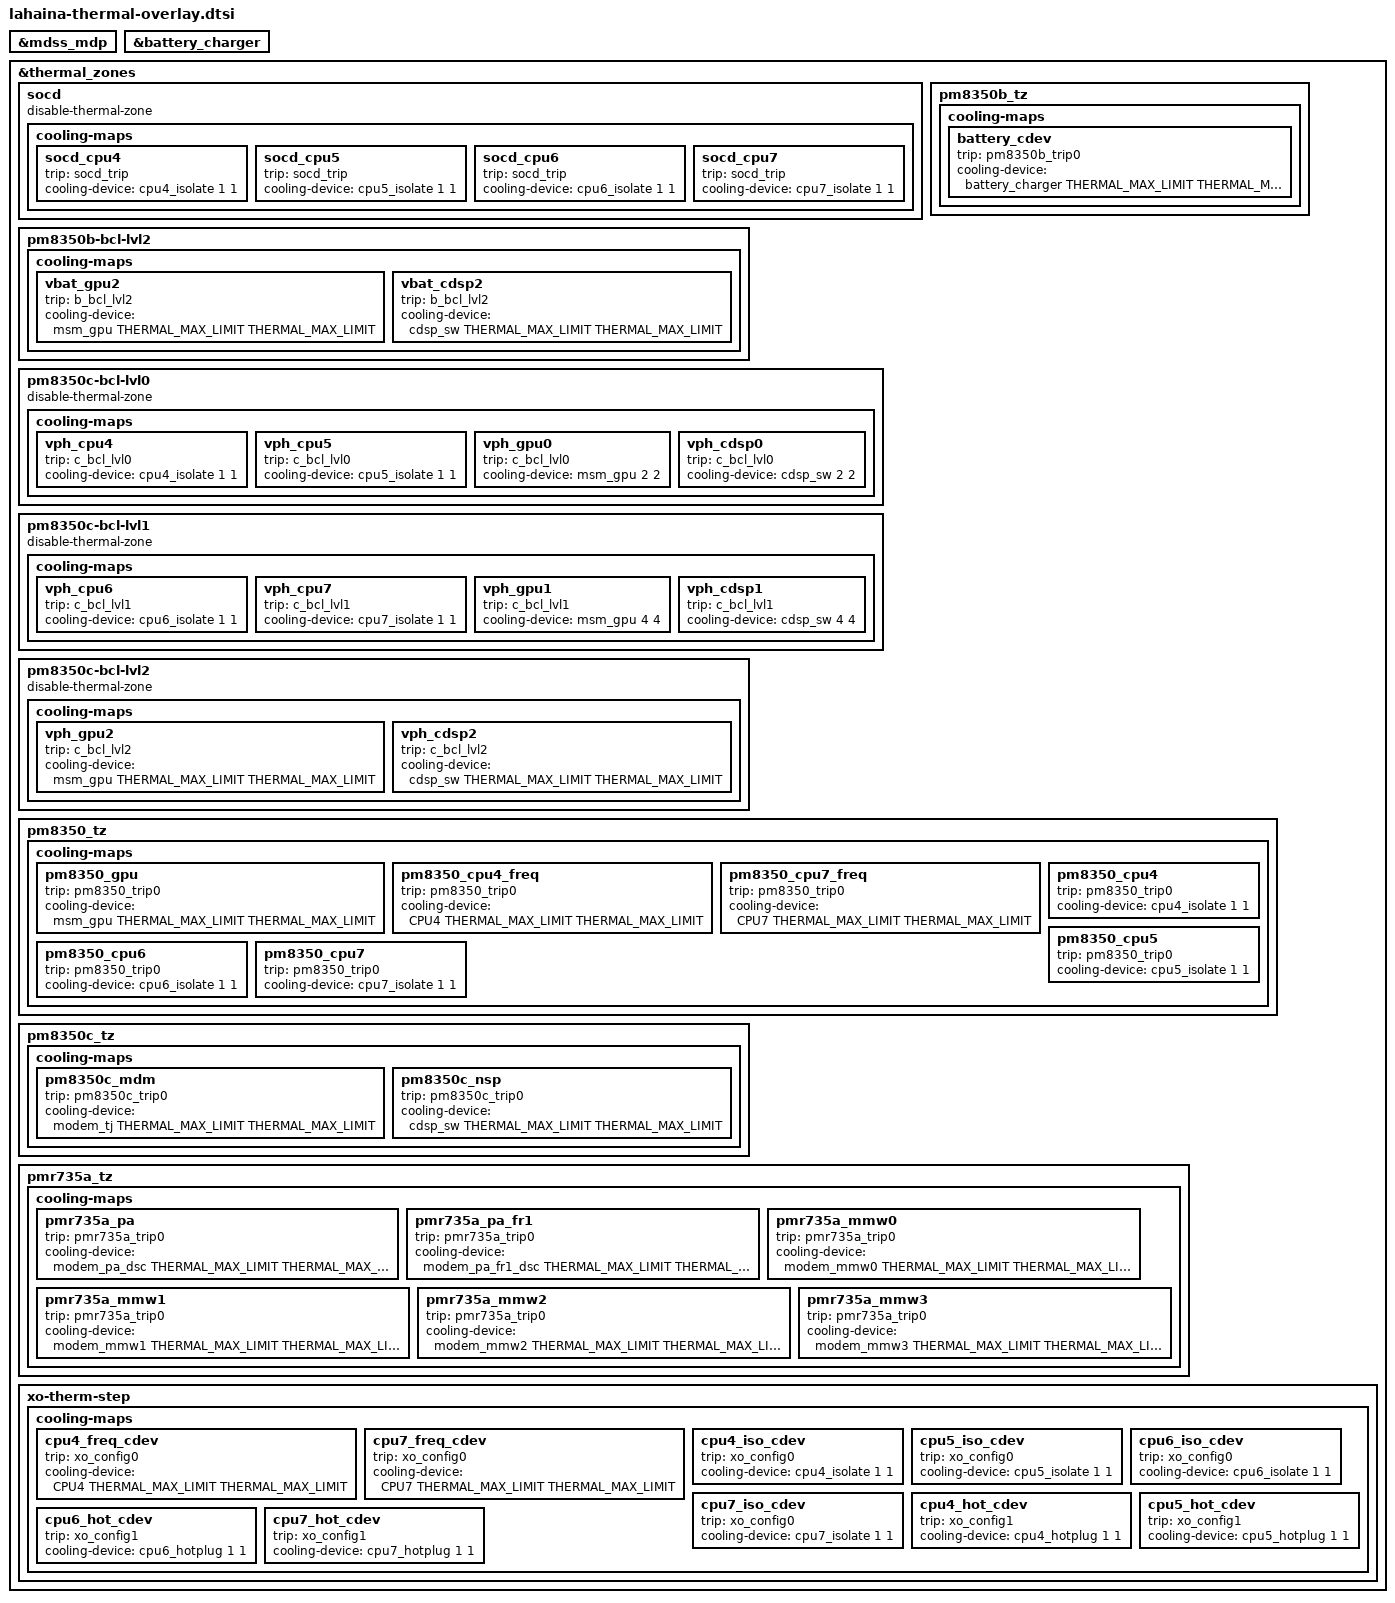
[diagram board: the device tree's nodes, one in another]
#include <dt-bindings/thermal/thermal_qti.h>

&mdss_mdp {
	#cooling-cells = <2>;
};

&battery_charger {
	#cooling-cells = <2>;
};

&thermal_zones {
	socd {
		disable-thermal-zone;
		cooling-maps {
			socd_cpu4 {
				trip = <&socd_trip>;
				cooling-device = <&cpu4_isolate 1 1>;
			};

			socd_cpu5 {
				trip = <&socd_trip>;
				cooling-device = <&cpu5_isolate 1 1>;
			};

			socd_cpu6 {
				trip = <&socd_trip>;
				cooling-device = <&cpu6_isolate 1 1>;
			};

			socd_cpu7 {
				trip = <&socd_trip>;
				cooling-device = <&cpu7_isolate 1 1>;
			};
		};
	};


/*	pm8350b-bcl-lvl0 {
		cooling-maps {
			vbat_cpu4 {
				trip = <&b_bcl_lvl0>;
				cooling-device = <&cpu4_isolate 1 1>;
			};

			vbat_cpu5 {
				trip = <&b_bcl_lvl0>;
				cooling-device = <&cpu5_isolate 1 1>;
			};

			vbat_gpu0 {
				trip = <&b_bcl_lvl0>;
				cooling-device = <&msm_gpu 2 2>;
			};

			vbat_cdsp0 {
				trip = <&b_bcl_lvl0>;
				cooling-device = <&cdsp_sw 2 2>;
			};
		};
	};

	pm8350b-bcl-lvl1 {
		cooling-maps {
			vbat_cpu6 {
				trip = <&b_bcl_lvl1>;
				cooling-device = <&cpu6_isolate 1 1>;
			};

			vbat_cpu7 {
				trip = <&b_bcl_lvl1>;
				cooling-device = <&cpu7_isolate 1 1>;
			};

			vbat_gpu1 {
				trip = <&b_bcl_lvl1>;
				cooling-device = <&msm_gpu 4 4>;
			};

			vbat_cdsp1 {
				trip = <&b_bcl_lvl1>;
				cooling-device = <&cdsp_sw 4 4>;
			};
		};
	};
*/
	pm8350b-bcl-lvl2 {
		cooling-maps {
			vbat_gpu2 {
				trip = <&b_bcl_lvl2>;
				cooling-device = <&msm_gpu THERMAL_MAX_LIMIT
							THERMAL_MAX_LIMIT>;
			};

			vbat_cdsp2 {
				trip = <&b_bcl_lvl2>;
				cooling-device = <&cdsp_sw THERMAL_MAX_LIMIT
							THERMAL_MAX_LIMIT>;
			};
		};
	};

	pm8350c-bcl-lvl0 {
		disable-thermal-zone;
		cooling-maps {
			vph_cpu4 {
				trip = <&c_bcl_lvl0>;
				cooling-device = <&cpu4_isolate 1 1>;
			};

			vph_cpu5 {
				trip = <&c_bcl_lvl0>;
				cooling-device = <&cpu5_isolate 1 1>;
			};

			vph_gpu0 {
				trip = <&c_bcl_lvl0>;
				cooling-device = <&msm_gpu 2 2>;
			};

			vph_cdsp0 {
				trip = <&c_bcl_lvl0>;
				cooling-device = <&cdsp_sw 2 2>;
			};
		};
	};

	pm8350c-bcl-lvl1 {
		disable-thermal-zone;
		cooling-maps {
			vph_cpu6 {
				trip = <&c_bcl_lvl1>;
				cooling-device = <&cpu6_isolate 1 1>;
			};

			vph_cpu7 {
				trip = <&c_bcl_lvl1>;
				cooling-device = <&cpu7_isolate 1 1>;
			};

			vph_gpu1 {
				trip = <&c_bcl_lvl1>;
				cooling-device = <&msm_gpu 4 4>;
			};

			vph_cdsp1 {
				trip = <&c_bcl_lvl1>;
				cooling-device = <&cdsp_sw 4 4>;
			};
		};
	};

	pm8350c-bcl-lvl2 {
		disable-thermal-zone;
		cooling-maps {
			vph_gpu2 {
				trip = <&c_bcl_lvl2>;
				cooling-device = <&msm_gpu THERMAL_MAX_LIMIT
							THERMAL_MAX_LIMIT>;
			};

			vph_cdsp2 {
				trip = <&c_bcl_lvl2>;
				cooling-device = <&cdsp_sw THERMAL_MAX_LIMIT
							THERMAL_MAX_LIMIT>;
			};
		};
	};

	pm8350b_tz {
		cooling-maps {
			battery_cdev {
				trip = <&pm8350b_trip0>;
				cooling-device = <&battery_charger
							THERMAL_MAX_LIMIT
							THERMAL_MAX_LIMIT>;
			};
		};
	};

	pm8350_tz {
		cooling-maps {
			pm8350_gpu {
				trip = <&pm8350_trip0>;
				cooling-device = <&msm_gpu THERMAL_MAX_LIMIT
							THERMAL_MAX_LIMIT>;
			};

			pm8350_cpu4_freq {
				trip = <&pm8350_trip0>;
				cooling-device = <&CPU4 THERMAL_MAX_LIMIT
							THERMAL_MAX_LIMIT>;
			};

			pm8350_cpu7_freq {
				trip = <&pm8350_trip0>;
				cooling-device = <&CPU7 THERMAL_MAX_LIMIT
							THERMAL_MAX_LIMIT>;
			};

			pm8350_cpu4 {
				trip = <&pm8350_trip0>;
				cooling-device = <&cpu4_isolate 1 1>;
			};

			pm8350_cpu5 {
				trip = <&pm8350_trip0>;
				cooling-device = <&cpu5_isolate 1 1>;
			};

			pm8350_cpu6 {
				trip = <&pm8350_trip0>;
				cooling-device = <&cpu6_isolate 1 1>;
			};

			pm8350_cpu7 {
				trip = <&pm8350_trip0>;
				cooling-device = <&cpu7_isolate 1 1>;
			};
		};
	};

	pm8350c_tz {
		cooling-maps {
			pm8350c_mdm {
				trip = <&pm8350c_trip0>;
				cooling-device = <&modem_tj THERMAL_MAX_LIMIT
							THERMAL_MAX_LIMIT>;
			};

			pm8350c_nsp {
				trip = <&pm8350c_trip0>;
				cooling-device = <&cdsp_sw THERMAL_MAX_LIMIT
							THERMAL_MAX_LIMIT>;
			};
		};
	};

	pmr735a_tz {
		cooling-maps {
			pmr735a_pa {
				trip = <&pmr735a_trip0>;
				cooling-device = <&modem_pa_dsc
							THERMAL_MAX_LIMIT
							THERMAL_MAX_LIMIT>;
			};

			pmr735a_pa_fr1 {
				trip = <&pmr735a_trip0>;
				cooling-device = <&modem_pa_fr1_dsc
							THERMAL_MAX_LIMIT
							THERMAL_MAX_LIMIT>;
			};

			pmr735a_mmw0 {
				trip = <&pmr735a_trip0>;
				cooling-device = <&modem_mmw0 THERMAL_MAX_LIMIT
							THERMAL_MAX_LIMIT>;
			};

			pmr735a_mmw1 {
				trip = <&pmr735a_trip0>;
				cooling-device = <&modem_mmw1 THERMAL_MAX_LIMIT
							THERMAL_MAX_LIMIT>;
			};

			pmr735a_mmw2 {
				trip = <&pmr735a_trip0>;
				cooling-device = <&modem_mmw2 THERMAL_MAX_LIMIT
							THERMAL_MAX_LIMIT>;
			};

			pmr735a_mmw3 {
				trip = <&pmr735a_trip0>;
				cooling-device = <&modem_mmw3 THERMAL_MAX_LIMIT
							THERMAL_MAX_LIMIT>;
			};
		};
	};

	xo-therm-step {
		cooling-maps {
			cpu4_freq_cdev {
				trip = <&xo_config0>;
				cooling-device = <&CPU4 THERMAL_MAX_LIMIT
							THERMAL_MAX_LIMIT>;
			};

			cpu7_freq_cdev {
				trip = <&xo_config0>;
				cooling-device = <&CPU7 THERMAL_MAX_LIMIT
							THERMAL_MAX_LIMIT>;
			};

			cpu4_iso_cdev {
				trip = <&xo_config0>;
				cooling-device = <&cpu4_isolate 1 1>;
			};

			cpu5_iso_cdev {
				trip = <&xo_config0>;
				cooling-device = <&cpu5_isolate 1 1>;
			};

			cpu6_iso_cdev {
				trip = <&xo_config0>;
				cooling-device = <&cpu6_isolate 1 1>;
			};

			cpu7_iso_cdev {
				trip = <&xo_config0>;
				cooling-device = <&cpu7_isolate 1 1>;
			};

			cpu4_hot_cdev {
				trip = <&xo_config1>;
				cooling-device = <&cpu4_hotplug 1 1>;
			};

			cpu5_hot_cdev {
				trip = <&xo_config1>;
				cooling-device = <&cpu5_hotplug 1 1>;
			};

			cpu6_hot_cdev {
				trip = <&xo_config1>;
				cooling-device = <&cpu6_hotplug 1 1>;
			};

			cpu7_hot_cdev {
				trip = <&xo_config1>;
				cooling-device = <&cpu7_hotplug 1 1>;
			};
		};
	};
};
